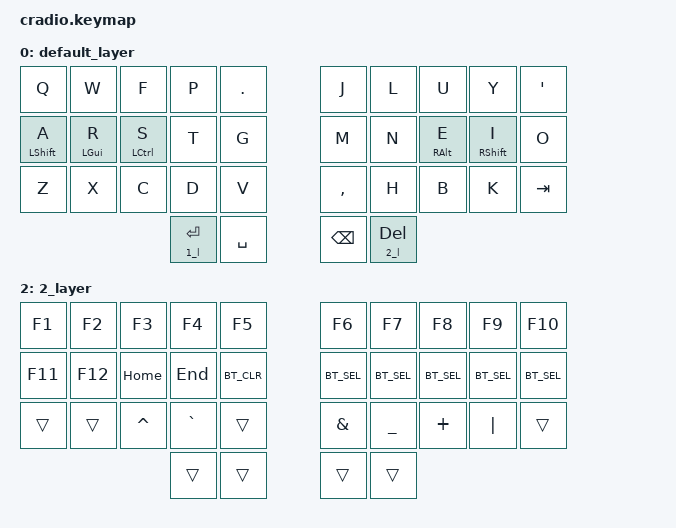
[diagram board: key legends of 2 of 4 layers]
// Copyright (c) 2022 The ZMK Contributors
// SPDX-License-Identifier: MIT

#include <behaviors.dtsi>
#include <dt-bindings/zmk/keys.h>
#include <dt-bindings/zmk/bt.h>



/ {
    behaviors {
        ht: hold_tap {
            label = "hold_tap";
            compatible = "zmk,behavior-hold-tap";
            #binding-cells = <2>;
            flavor = "tap-preferred";
            tapping-term-ms = <700>;
            quick-tap-ms = <600>;
            global-quick-tap;
            bindings = <&kp>, <&kp>;
        };
    };

    conditional_layers {
        compatible = "zmk,conditional-layers";
        3_layer {
            if-layers = <1 2>;
            then-layer = <3>;
        };
    };

    keymap {
        compatible = "zmk,keymap";
        default_layer {
            bindings = <
        //╭──────────┬──────────┬──────────┬──────────┬──────────╮   ╭──────────┬──────────┬──────────┬──────────┬──────────╮
        //│  Q       │  W       │  F       │  P       │  ./>     │   │  J       │  L       │  U       │  Y       │  '/"     │
            &kp Q      &kp W      &kp F      &kp P      &kp PERIOD     &kp J      &kp L      &kp U      &kp Y      &kp SQT
        //├──────────┼──────────┼──────────┼──────────┼──────────┤   ├──────────┼──────────┼──────────┼──────────┼──────────┤
        //│ SHFT|A   │  GUI|R   │  CTRL|S  │  T       │  G       │   │  M       │  N       │  ALT|E   │  SHFT|I  │   O      │
           &hm LSHFT A &hm LGUI R &hm LCTRL S &kp T     &kp G          &kp M      &kp N      &hm RALT E &hm RSHFT I &kp O
        //├──────────┼──────────┼──────────┼──────────┼──────────┤   ├──────────┼──────────┼──────────┼──────────┼──────────┤
        //│  Z       │  X       │  C       │  D       │  V       │   │  ,/<     │  H       │   B      │ K        │   TAB    │
            &kp Z      &kp X      &kp C      &kp D      &kp V          &kp COMMA  &kp H       &kp B    &kp K       &kp TAB
        //╰──────────┴──────────┴──────────┼──────────┼──────────┤   ├──────────┼──────────┼──────────┴──────────┴──────────╯
                                           &lt 1_l ENTER &kp SPACE      &kp BKSP   &lt 2_l DEL
        //                                 ╰──────────┴──────────╯   ╰──────────┴──────────╯
            >;
        };

        1_layer {
            bindings = <
        //╭──────────┬──────────┬──────────┬──────────┬──────────╮   ╭──────────┬──────────┬──────────┬──────────┬──────────╮
        //│   ESC    │  UP ARW  │  _       │  /       │    &     │   │ENTER     │    7     │     8    │   9      │    ;/:   │
            &kp ESC    &kp UARW   &kp UNDER  &kp FSLH   &kp AMPS      &kp ENTER   &kp N7     &kp N8    &kp N9      &kp SEMI
        //├──────────┼──────────┼──────────┼──────────┼──────────┤   ├──────────┼──────────┼──────────┼──────────┼──────────┤
        //│ LEFT ARW │ DOWN ARW │ RGHT ARW │   SHFT   │    (     │   │    )     │     4    │   5      │    6     │   0      │
            &kp LARW    &kp DARW     &kp RARW  &kp RSHFT   &kp LPAR     &kp RPAR   &kp N4      &kp N5    V&kp N6     &kp N0
        //├──────────┼──────────┼──────────┼──────────┼──────────┤   ├──────────┼──────────┼──────────┼──────────┼──────────┤
        //│ CAPS LCK │  =       │  ~       │  [       │  ]       │   │   +      │   1      │   2      │   3      │   \/|    │
           &kp CAPS    &kp EQUAL     &kp TILDA &kp LBKT   &kp RBKT      &kp PLUS   &kp N1     &kp N2     &kp N3      &kp BSLH
        //╰──────────┴──────────┴──────────┼──────────┼──────────┤   ├──────────┼──────────┼──────────┴──────────┴──────────╯
                                             &trans     &trans          &trans     &trans
        //                                 ╰──────────┴──────────╯   ╰──────────┴──────────╯
            >;
        };

        2_layer {
            bindings = <
        //╭──────────┬──────────┬──────────┬──────────┬──────────╮   ╭──────────┬──────────┬──────────┬──────────┬──────────╮
        //│    F1    │   F2     │  F3      │  F4      │  F5      │   │    F6    │  F7      │  F8      │  F9      │  F10     │
            &kp F1     &kp F2    &kp F3     &kp F4     &kp F5         &kp F6     &kp F7      &kp F8     &kp F9     &kp F10
        //├──────────┼──────────┼──────────┼──────────┼──────────┤   ├──────────┼──────────┼──────────┼──────────┼──────────┤
        //│   F11    │  F12     │   HOME   │   END    │  BT CLR  │   │  BT SEL0 │  BT SEL1 │  BT SEL2 │  BT SEL3 │  BT SEL4 │
            &kp F11   &kp F12    &kp HOME   &kp END    &kp BT_CLR   &kp BT_SEL 0 &kp BT_SEL 1 &kp BT_SEL 2 &kp BT_SEL 3 &kp BT_SEL 4
        //├──────────┼──────────┼──────────┼──────────┼──────────┤   ├──────────┼──────────┼──────────┼──────────┼──────────┤
        //│          │          │    ^     │    `     │          │   │  &       │  _       │  +       │  │       │          │
            &trans     &trans     &kp CARET   &kp GRAVE  &trans         &kp AMPS   &kp UNDER  &kp PLUS   &kp PIPE   &trans
        //╰──────────┴──────────┴──────────┼──────────┼──────────┤   ├──────────┼──────────┼──────────┴──────────┴──────────╯
                                             &trans     &trans         &trans     &trans
        //                                 ╰──────────┴──────────╯   ╰──────────┴──────────╯
            >;
        };

        3_layer {
            bindings = <
        //╭──────────┬──────────┬──────────┬──────────┬──────────╮   ╭──────────┬──────────┬──────────┬──────────┬──────────╮
        //│ RESET    │          │          │          │PROFILE 0 │   │          │          │          │          │  RESET   │
        // &sys_reset  &trans     &trans     &trans    &bt BT_SEL 0    &trans     &trans     &trans     &trans    &sys_reset
        //├──────────┼──────────┼──────────┼──────────┼──────────┤   ├──────────┼──────────┼──────────┼──────────┼──────────┤
        //│BOOTLOADER│          │          │          │PROFILE 1 │   │          │          │          │          │BOOTLOADER│
        //&bootloader  &trans     &trans     &trans    &bt BT_SEL 1    &trans     &trans     &trans     &trans    &bootloader
        //├──────────┼──────────┼──────────┼──────────┼──────────┤   ├──────────┼──────────┼──────────┼──────────┼──────────┤
        //│          │          │          │ CLEAR BT │PROFILE 2 │   │          │          │          │          │          │
        //  &trans     &trans     &trans    &bt BT_CLR &bt BT_SEL 2    &trans     &trans     &trans     &trans     &trans
        //╰──────────┴──────────┴──────────┼──────────┼──────────┤   ├──────────┼──────────┼──────────┴──────────┴──────────╯
                                             &trans     &trans         &trans     &trans
        //                                 ╰──────────┴──────────╯   ╰──────────┴──────────╯
            >;
        };
    };
};
